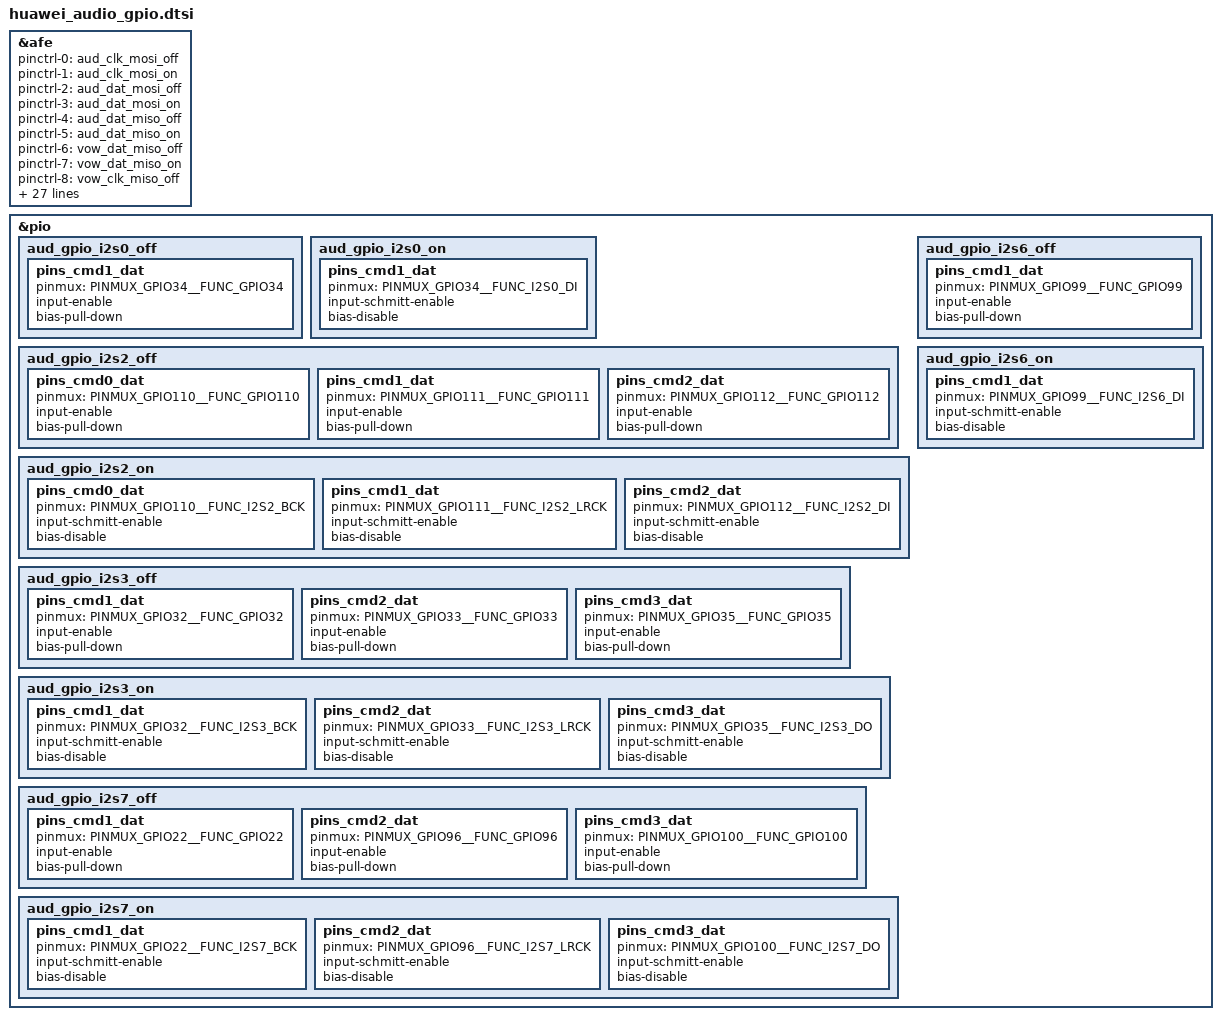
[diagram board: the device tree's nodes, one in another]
&afe {
	pinctrl-names = "aud_clk_mosi_off",
			"aud_clk_mosi_on",
			"aud_dat_mosi_off",
			"aud_dat_mosi_on",
			"aud_dat_miso_off",
			"aud_dat_miso_on",
			"vow_dat_miso_off",
			"vow_dat_miso_on",
			"vow_clk_miso_off",
			"vow_clk_miso_on",
			"aud_nle_mosi_off",
			"aud_nle_mosi_on",
			"aud_dat_miso2_off",
			"aud_dat_miso2_on",
			"aud_gpio_i2s0_off",
			"aud_gpio_i2s0_on",
			"aud_gpio_i2s1_off",
			"aud_gpio_i2s1_on",
			"aud_gpio_i2s2_off",
			"aud_gpio_i2s2_on",
			"aud_gpio_i2s3_off",
			"aud_gpio_i2s3_on",
			"aud_gpio_i2s5_off",
			"aud_gpio_i2s5_on",
			"aud_gpio_i2s6_off",
			"aud_gpio_i2s6_on",
			"aud_gpio_i2s7_off",
			"aud_gpio_i2s7_on",
			"aud_gpio_i2s8_off",
			"aud_gpio_i2s8_on",
			"aud_gpio_i2s9_off",
			"aud_gpio_i2s9_on",
			"aud_dat_mosi_ch34_off",
			"aud_dat_mosi_ch34_on",
			"aud_dat_miso_ch34_off",
			"aud_dat_miso_ch34_on";
	pinctrl-0 = <&aud_clk_mosi_off>;
	pinctrl-1 = <&aud_clk_mosi_on>;
	pinctrl-2 = <&aud_dat_mosi_off>;
	pinctrl-3 = <&aud_dat_mosi_on>;
	pinctrl-4 = <&aud_dat_miso_off>;
	pinctrl-5 = <&aud_dat_miso_on>;
	pinctrl-6 = <&vow_dat_miso_off>;
	pinctrl-7 = <&vow_dat_miso_on>;
	pinctrl-8 = <&vow_clk_miso_off>;
	pinctrl-9 = <&vow_clk_miso_on>;
	pinctrl-10 = <&aud_nle_mosi_off>;
	pinctrl-11 = <&aud_nle_mosi_on>;
	pinctrl-12 = <&aud_dat_miso2_off>;
	pinctrl-13 = <&aud_dat_miso2_on>;
	pinctrl-14 = <&aud_gpio_i2s0_off>;
	pinctrl-15 = <&aud_gpio_i2s0_on>;
	pinctrl-16 = <&aud_gpio_i2s1_off>;
	pinctrl-17 = <&aud_gpio_i2s1_on>;
	pinctrl-18 = <&aud_gpio_i2s2_off>;
	pinctrl-19 = <&aud_gpio_i2s2_on>;
	pinctrl-20 = <&aud_gpio_i2s3_off>;
	pinctrl-21 = <&aud_gpio_i2s3_on>;
	pinctrl-22 = <&aud_gpio_i2s5_off>;
	pinctrl-23 = <&aud_gpio_i2s5_on>;
	pinctrl-24 = <&aud_gpio_i2s6_off>;
	pinctrl-25 = <&aud_gpio_i2s6_on>;
	pinctrl-26 = <&aud_gpio_i2s7_off>;
	pinctrl-27 = <&aud_gpio_i2s7_on>;
	pinctrl-28 = <&aud_gpio_i2s8_off>;
	pinctrl-29 = <&aud_gpio_i2s8_on>;
	pinctrl-30 = <&aud_gpio_i2s9_off>;
	pinctrl-31 = <&aud_gpio_i2s9_on>;
	pinctrl-32 = <&aud_dat_mosi_ch34_off>;
	pinctrl-33 = <&aud_dat_mosi_ch34_on>;
	pinctrl-34 = <&aud_dat_miso_ch34_off>;
	pinctrl-35 = <&aud_dat_miso_ch34_on>;
	status = "okay";
};

&pio {
	aud_gpio_i2s0_off: aud_gpio_i2s0_off {
		pins_cmd1_dat {
			pinmux = <PINMUX_GPIO34__FUNC_GPIO34>;
			input-enable;
			bias-pull-down;
		};
	};
	aud_gpio_i2s0_on: aud_gpio_i2s0_on {
		pins_cmd1_dat {
			pinmux = <PINMUX_GPIO34__FUNC_I2S0_DI>;
			input-schmitt-enable;
			bias-disable;
		};
	};
	aud_gpio_i2s2_off: aud_gpio_i2s2_off {
		pins_cmd0_dat {
			pinmux = <PINMUX_GPIO110__FUNC_GPIO110>;
			input-enable;
			bias-pull-down;
		};
		pins_cmd1_dat {
			pinmux = <PINMUX_GPIO111__FUNC_GPIO111>;
			input-enable;
			bias-pull-down;
		};
		pins_cmd2_dat {
			pinmux = <PINMUX_GPIO112__FUNC_GPIO112>;
			input-enable;
			bias-pull-down;
		};
	};
	aud_gpio_i2s2_on: aud_gpio_i2s2_on {
		pins_cmd0_dat {
			pinmux = <PINMUX_GPIO110__FUNC_I2S2_BCK>;
			input-schmitt-enable;
			bias-disable;
		};
		pins_cmd1_dat {
			pinmux = <PINMUX_GPIO111__FUNC_I2S2_LRCK>;
			input-schmitt-enable;
			bias-disable;
		};
		pins_cmd2_dat {
			pinmux = <PINMUX_GPIO112__FUNC_I2S2_DI>;
			input-schmitt-enable;
			bias-disable;
		};
	};
	aud_gpio_i2s3_off: aud_gpio_i2s3_off {
		pins_cmd1_dat {
			pinmux = <PINMUX_GPIO32__FUNC_GPIO32>;
			input-enable;
			bias-pull-down;
		};
		pins_cmd2_dat {
			pinmux = <PINMUX_GPIO33__FUNC_GPIO33>;
			input-enable;
			bias-pull-down;
		};
		pins_cmd3_dat {
			pinmux = <PINMUX_GPIO35__FUNC_GPIO35>;
			input-enable;
			bias-pull-down;
		};
	};
	aud_gpio_i2s3_on: aud_gpio_i2s3_on {
		pins_cmd1_dat {
			pinmux = <PINMUX_GPIO32__FUNC_I2S3_BCK>;
			input-schmitt-enable;
			bias-disable;
		};
		pins_cmd2_dat {
			pinmux = <PINMUX_GPIO33__FUNC_I2S3_LRCK>;
			input-schmitt-enable;
			bias-disable;
		};
		pins_cmd3_dat {
			pinmux = <PINMUX_GPIO35__FUNC_I2S3_DO>;
			input-schmitt-enable;
			bias-disable;
		};
	};

	aud_gpio_i2s6_off: aud_gpio_i2s6_off {
			pins_cmd1_dat {
			pinmux = <PINMUX_GPIO99__FUNC_GPIO99>;
			input-enable;
			bias-pull-down;
		};
	};
	aud_gpio_i2s6_on: aud_gpio_i2s6_on {
			pins_cmd1_dat {
			pinmux = <PINMUX_GPIO99__FUNC_I2S6_DI>;
			input-schmitt-enable;
			bias-disable;
		};
	};
	aud_gpio_i2s7_off: aud_gpio_i2s7_off {
		pins_cmd1_dat {
			pinmux = <PINMUX_GPIO22__FUNC_GPIO22>;
			input-enable;
			bias-pull-down;
		};
		pins_cmd2_dat {
			pinmux = <PINMUX_GPIO96__FUNC_GPIO96>;
			input-enable;
			bias-pull-down;
		};
		pins_cmd3_dat {
			pinmux = <PINMUX_GPIO100__FUNC_GPIO100>;
			input-enable;
			bias-pull-down;
		};
	};
	aud_gpio_i2s7_on: aud_gpio_i2s7_on {
		pins_cmd1_dat {
			pinmux = <PINMUX_GPIO22__FUNC_I2S7_BCK>;
			input-schmitt-enable;
			bias-disable;
		};
		pins_cmd2_dat {
			pinmux = <PINMUX_GPIO96__FUNC_I2S7_LRCK>;
			input-schmitt-enable;
			bias-disable;
		};
		pins_cmd3_dat {
			pinmux = <PINMUX_GPIO100__FUNC_I2S7_DO>;
			input-schmitt-enable;
			bias-disable;
		};
	};
};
